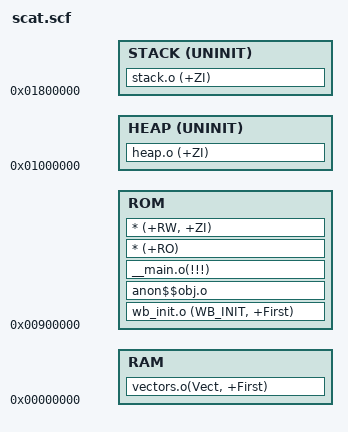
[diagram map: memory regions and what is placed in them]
;/**************************************************************************//**
; * @file     scat.scf
; * @brief    N32905 series scatter code
; *
; * SPDX-License-Identifier: Apache-2.0
; * @copyright (C) 2020 Nuvoton Technology Corp. All rights reserved.
; *****************************************************************************/


ROM_LOAD 0x900000
{
    ROM +0
    {
        wb_init.o (WB_INIT, +First)
        anon$$obj.o
        __main.o(!!!)
        * (+RO)
        * (+RW, +ZI) 
        
    }
    
    RAM 0x0
    {
        vectors.o(Vect, +First)  
    }
      
    
    ;HEAP 0xC00000 UNINIT
    HEAP 0x1000000 UNINIT
    {
        heap.o (+ZI)
    }

	;STACK 0x1000000 UNINIT
	STACK 0x1800000 UNINIT
	{
		stack.o (+ZI)
	}    
}
